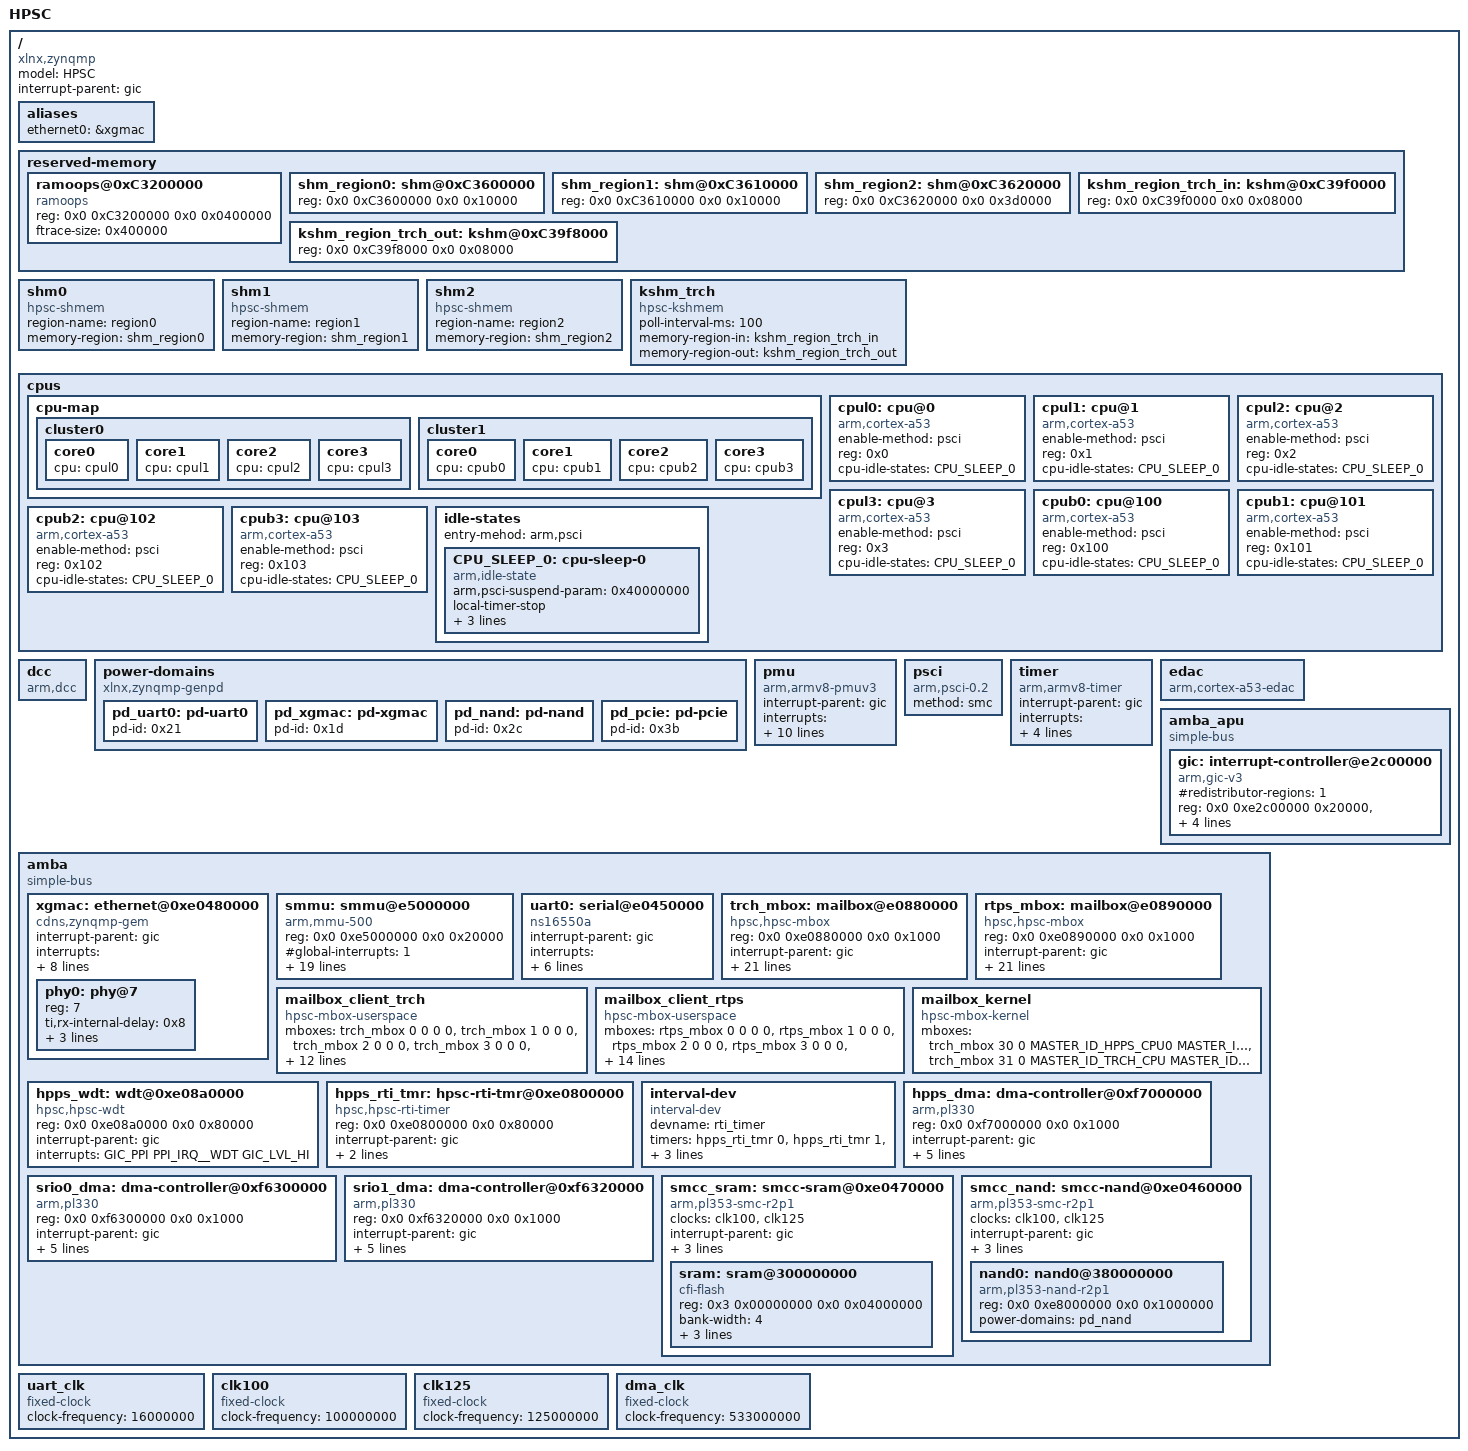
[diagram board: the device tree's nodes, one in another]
/dts-v1/;

#include <dt-bindings/phy/phy.h>

/* Copies from Qemu Device Tree repo */
#include "hpsc-irqs.dtsh"
#include "hpsc-busids.dtsh"

#include "mailbox-map.h" /* same file also present in other subsystems */

#define GIC_SPI 0
#define GIC_PPI 1
#define GIC_EDGE_RISE 1
#define GIC_EDGE_FALL 2
#define GIC_EDGE_BOTH 3
#define GIC_LVL_HI 4
#define GIC_LVL_LO 8

/ {
	model = "HPSC";
	compatible = "xlnx,zynqmp";
	#address-cells = <2>;
	#size-cells = <2>;

	interrupt-parent = <&gic>;
	aliases {
		ethernet0 = &xgmac;
	};

        /* NOTE: memory { } nodes appended by u-boot from its device tree */

	reserved-memory { /* TOOD: confirm that this is respected, also can/should this be in u-boot DT? */
		#address-cells = <2>;
		#size-cells = <2>;
		ranges;

		ramoops@0xC3200000 {
			compatible = "ramoops";
			reg = <0x0 0xC3200000 0x0 0x0400000>;
			ftrace-size = <0x400000>;
		};

		/* These shared memory regions cover the following range: */
		/* reg = <0x0 0xbf800000 0x0 0x400000>; */
		/* First part of the memory is for userspace */
		/* outbound to TRCH */
		shm_region0: shm@0xC3600000 {
			reg = <0x0 0xC3600000 0x0 0x10000>;
		};
		/* inbound from TRCH */
		shm_region1: shm@0xC3610000 {
			reg = <0x0 0xC3610000 0x0 0x10000>;
		};
		/* currently unused */
		shm_region2: shm@0xC3620000 {
			reg = <0x0 0xC3620000 0x0 0x3d0000>;
		};
		/* Remaining part of the memory is for the kernel */
		kshm_region_trch_in: kshm@0xC39f0000 {
			reg = <0x0 0xC39f0000 0x0 0x08000>;
		};
		kshm_region_trch_out: kshm@0xC39f8000 {
			reg = <0x0 0xC39f8000 0x0 0x08000>;
		};
	};

	shm0 {
		compatible = "hpsc-shmem";
		region-name = "region0";
		memory-region = <&shm_region0>;
	};
	shm1 {
		compatible = "hpsc-shmem";
		region-name = "region1";
		memory-region = <&shm_region1>;
	};
	shm2 {
		compatible = "hpsc-shmem";
		region-name = "region2";
		memory-region = <&shm_region2>;
	};
	kshm_trch {
		compatible = "hpsc-kshmem";
		poll-interval-ms = <100>;
		memory-region-in = <&kshm_region_trch_in>;
		memory-region-out = <&kshm_region_trch_out>;
	};

	cpus {
		#address-cells = <1>;
		#size-cells = <0>;

		cpu-map {
			cluster0 {
				core0 {
					cpu = <&cpul0>;
				};
				core1 {
					cpu = <&cpul1>;
				};
				core2 {
					cpu = <&cpul2>;
				};
				core3 {
					cpu = <&cpul3>;
				};
			};
			cluster1 {
				core0 {
					cpu = <&cpub0>;
				};
				core1 {
					cpu = <&cpub1>;
				};
				core2 {
					cpu = <&cpub2>;
				};
				core3 {
					cpu = <&cpub3>;
				};
			};

		};
         
		cpul0: cpu@0 {
			compatible = "arm,cortex-a53", "arm,armv8";
			device_type = "cpu";
			enable-method = "psci";
			reg = <0x0>;
			cpu-idle-states = <&CPU_SLEEP_0>;
		};

		cpul1: cpu@1 {
			compatible = "arm,cortex-a53", "arm,armv8";
			device_type = "cpu";
			enable-method = "psci";
			reg = <0x1>;
			cpu-idle-states = <&CPU_SLEEP_0>;
		};

		cpul2: cpu@2 {
			compatible = "arm,cortex-a53", "arm,armv8";
			device_type = "cpu";
			enable-method = "psci";
			reg = <0x2>;
			cpu-idle-states = <&CPU_SLEEP_0>;
		};

		cpul3: cpu@3 {
			compatible = "arm,cortex-a53", "arm,armv8";
			device_type = "cpu";
			enable-method = "psci";
			reg = <0x3>;
			cpu-idle-states = <&CPU_SLEEP_0>;
		};

		cpub0: cpu@100 {
			compatible = "arm,cortex-a53", "arm,armv8";
			device_type = "cpu";
			enable-method = "psci";
			reg = <0x100>;
			cpu-idle-states = <&CPU_SLEEP_0>;
		};

		cpub1: cpu@101 {
			compatible = "arm,cortex-a53", "arm,armv8";
			device_type = "cpu";
			enable-method = "psci";
			reg = <0x101>;
			cpu-idle-states = <&CPU_SLEEP_0>;
		};

		cpub2: cpu@102 {
			compatible = "arm,cortex-a53", "arm,armv8";
			device_type = "cpu";
			enable-method = "psci";
			reg = <0x102>;
			cpu-idle-states = <&CPU_SLEEP_0>;
		};

		cpub3: cpu@103 {
			compatible = "arm,cortex-a53", "arm,armv8";
			device_type = "cpu";
			enable-method = "psci";
			reg = <0x103>;
			cpu-idle-states = <&CPU_SLEEP_0>;
		};

		idle-states {
			entry-mehod = "arm,psci";

			CPU_SLEEP_0: cpu-sleep-0 {
				compatible = "arm,idle-state";
				arm,psci-suspend-param = <0x40000000>;
				local-timer-stop;
				entry-latency-us = <300>;
				exit-latency-us = <600>;
				min-residency-us = <800000>;
			};
		};
	};

	dcc: dcc {
		compatible = "arm,dcc";
		status = "okay";
	};

	power-domains {
		compatible = "xlnx,zynqmp-genpd";

		pd_uart0: pd-uart0 {
			#power-domain-cells = <0x0>;
			pd-id = <0x21>;
		};

		pd_xgmac: pd-xgmac {
			#power-domain-cells = <0x0>;
			pd-id = <0x1d>;
		};

		pd_nand: pd-nand {
			#power-domain-cells = <0x0>;
			pd-id = <0x2c>;
		};

		pd_pcie: pd-pcie {
			#power-domain-cells = <0x0>;
			pd-id = <0x3b>;
		};
	};

	pmu {
		compatible = "arm,armv8-pmuv3";
		interrupt-parent = <&gic>;
		interrupts = <GIC_SPI HPPS_IRQ__PMU_0 GIC_LVL_HI>,
			     <GIC_SPI HPPS_IRQ__PMU_1 GIC_LVL_HI>,
			     <GIC_SPI HPPS_IRQ__PMU_2 GIC_LVL_HI>,
			     <GIC_SPI HPPS_IRQ__PMU_3 GIC_LVL_HI>,
			     <GIC_SPI HPPS_IRQ__PMU_4 GIC_LVL_HI>,
			     <GIC_SPI HPPS_IRQ__PMU_5 GIC_LVL_HI>,
			     <GIC_SPI HPPS_IRQ__PMU_6 GIC_LVL_HI>,
			     <GIC_SPI HPPS_IRQ__PMU_7 GIC_LVL_HI>;
		interrupt-affinity = <&cpul0>, <&cpul1>, <&cpul2>, <&cpul3>,
                                     <&cpub0>, <&cpub1>, <&cpub2>, <&cpub3>;
	};

	psci {
		compatible = "arm,psci-0.2";
		method = "smc";
	};

	timer {
		compatible = "arm,armv8-timer";
		interrupt-parent = <&gic>;
		interrupts = <GIC_PPI PPI_IRQ__TIMER_SEC  GIC_LVL_LO>,
			     <GIC_PPI PPI_IRQ__TIMER_PHYS GIC_LVL_LO>,
			     <GIC_PPI PPI_IRQ__TIMER_VIRT GIC_LVL_LO>,
			     <GIC_PPI PPI_IRQ__TIMER_HYP  GIC_LVL_LO>;
	};

	edac {
		compatible = "arm,cortex-a53-edac";
	};

	amba_apu: amba_apu {
		compatible = "simple-bus";
		#address-cells = <2>;
		#size-cells = <1>;
		ranges = <0 0 0 0 0xffffffff>;

		gic: interrupt-controller@e2c00000{
			compatible = "arm,gic-v3"; 
			#interrupt-cells = <3>;
			#redistributor-regions = <1>;
			reg = <0x0 0xe2c00000 0x20000>,
			      <0x0 0xe2d00000 0x100000>;
			interrupt-controller;
			interrupts = <GIC_PPI PPI_IRQ__GIC_MAINT GIC_LVL_HI>;
		};
	};

	amba: amba {
		compatible = "simple-bus";
		#address-cells = <2>;
		#size-cells = <2>;
		ranges;

		xgmac: ethernet@0xe0480000{
			compatible = "cdns,zynqmp-gem";
			status = "okay";
			interrupt-parent = <&gic>;
			interrupts = <GIC_SPI HPPS_IRQ__XGMAC      GIC_LVL_HI>,
                                     <GIC_SPI HPPS_IRQ__XGMAC_WAKE GIC_LVL_HI>;
			reg = <0x0 0xe0480000 0x0 0x1000>;
			clocks = <&clk125>, <&clk125>, <&clk125>;
			clock-names = "pclk", "hclk", "tx_clk";
			#address-cells = <1>;
			#size-cells = <0>;
			iommus = <&smmu MASTER_ID_XGMAC>;
			power-domains = <&pd_xgmac>;
			phy-handle = <&phy0>;
			phy-mode = "rgmii-id";

			phy0: phy@7 {
				reg = <7>;
				ti,rx-internal-delay = <0x8>;
				ti,tx-internal-delay = <0xa>;
				ti,fifo-depth = <0x1>;
				ti,rxctrl-strap-worka;
			};
		};

#if 0 /* TODO */
		pcie: pcie@0xe5330000 {
			compatible = "xlnx,nwl-pcie-2.11";
			status = "okay";
			#address-cells = <3>;
			#size-cells = <2>;
			#interrupt-cells = <1>;
			msi-controller;
			device_type = "pci";
			interrupt-parent = <&gic>;
			interrupts = <GIC_SPI ? GIC_LVL_HI>,
				     <GIC_SPI ? GIC_LVL_HI>,
				     <GIC_SPI ? GIC_LVL_HI>,
				     <GIC_SPI ? GIC_LVL_HI>,	/* MSI_1 [63...32] */
				     <GIC_SPI ? GIC_LVL_HI>;	/* MSI_0 [31...0] */
			interrupt-names = "misc","dummy","intx", "msi1", "msi0";
			msi-parent = <&pcie>;
			reg = <0x0 0xe5330000 0x0 0x1000>,
			      <0x0 0xe53d0000 0x0 0x1000>,
			      <0x80 0x00000000 0x0 0x1000000>;
			reg-names = "breg", "pcireg", "cfg";
			ranges = <0x02000000 0x00000000 0xe0000000 0x00000000 0xe0000000 0x00000000 0x10000000	/* non-prefetchable memory */
				  0x43000000 0x00000006 0x00000000 0x00000006 0x00000000 0x00000002 0x00000000>;/* prefetchable memory */
			interrupt-map-mask = <0x0 0x0 0x0 0x7>;
			interrupt-map = <0x0 0x0 0x0 0x1 &pcie_intc 0x1>,
					<0x0 0x0 0x0 0x2 &pcie_intc 0x2>,
					<0x0 0x0 0x0 0x3 &pcie_intc 0x3>,
					<0x0 0x0 0x0 0x4 &pcie_intc 0x4>;
			power-domains = <&pd_pcie>;
			pcie_intc: legacy-interrupt-controller {
				interrupt-controller;
				#address-cells = <0>;
				#interrupt-cells = <1>;
			};
		};
#endif

		smmu: smmu@e5000000{
			compatible = "arm,mmu-500";
			reg = <0x0 0xe5000000 0x0 0x20000>;
			#iommu-cells = <1>;
			#global-interrupts = <1>;
			interrupt-parent = <&gic>;
			interrupts = <GIC_SPI HPPS_IRQ__HPPS_SMMU_GLOB GIC_LVL_HI>, /* global irq */
                                /* context IRQs */
                                <GIC_SPI HPPS_IRQ__HPPS_SMMU_CB_0 GIC_LVL_HI>,
                                <GIC_SPI HPPS_IRQ__HPPS_SMMU_CB_1 GIC_LVL_HI>,
                                <GIC_SPI HPPS_IRQ__HPPS_SMMU_CB_2 GIC_LVL_HI>,
                                <GIC_SPI HPPS_IRQ__HPPS_SMMU_CB_3 GIC_LVL_HI>,
                                <GIC_SPI HPPS_IRQ__HPPS_SMMU_CB_4 GIC_LVL_HI>,
                                <GIC_SPI HPPS_IRQ__HPPS_SMMU_CB_5 GIC_LVL_HI>,
                                <GIC_SPI HPPS_IRQ__HPPS_SMMU_CB_6 GIC_LVL_HI>,
                                <GIC_SPI HPPS_IRQ__HPPS_SMMU_CB_7 GIC_LVL_HI>,
                                <GIC_SPI HPPS_IRQ__HPPS_SMMU_CB_8 GIC_LVL_HI>,
                                <GIC_SPI HPPS_IRQ__HPPS_SMMU_CB_9 GIC_LVL_HI>,
                                <GIC_SPI HPPS_IRQ__HPPS_SMMU_CB_10 GIC_LVL_HI>,
                                <GIC_SPI HPPS_IRQ__HPPS_SMMU_CB_11 GIC_LVL_HI>,
                                <GIC_SPI HPPS_IRQ__HPPS_SMMU_CB_12 GIC_LVL_HI>,
                                <GIC_SPI HPPS_IRQ__HPPS_SMMU_CB_13 GIC_LVL_HI>,
                                <GIC_SPI HPPS_IRQ__HPPS_SMMU_CB_14 GIC_LVL_HI>,
                                <GIC_SPI HPPS_IRQ__HPPS_SMMU_CB_15 GIC_LVL_HI>;
		};

		uart0: serial@e0450000 {
			compatible = "ns16550a";
			/* compatible = "snps,dw-apb-uart"; */ /* TODO: fails with unassigned access */
			status = "okay";
			interrupt-parent = <&gic>;
			interrupts = <GIC_SPI HPPS_IRQ__HPPS_UART0_0 GIC_LVL_HI>;
			reg = <0x0 0xe0450000 0x0 0x1000>;
			current-speed = <125000>;
			reg-shift = <2>;
			clocks = <&uart_clk &uart_clk>;
			clock-names = "uart_clk", "pclk";
			power-domains = <&pd_uart0>;
		};

		trch_mbox: mailbox@e0880000{
			compatible = "hpsc,hpsc-mbox";
                        reg = <0x0 0xe0880000 0x0 0x1000>;
			interrupt-parent = <&gic>;

			/* Define all, but only two will be used, selected by
			 * interrupt-idx-{rcv,ack} props. We can't only list
			 * the two in this list, because the driver needs the
			 * actual within-ip-block index of the interrupt (and
			 * if we do, we'd still need an extra property to define
			 * the starting irq number, which is worse. */
			interrupts = <GIC_SPI HPPS_IRQ__HT_MBOX_0  GIC_LVL_HI>,
				     <GIC_SPI HPPS_IRQ__HT_MBOX_1  GIC_LVL_HI>,
				     <GIC_SPI HPPS_IRQ__HT_MBOX_2  GIC_LVL_HI>,
				     <GIC_SPI HPPS_IRQ__HT_MBOX_3  GIC_LVL_HI>,
				     <GIC_SPI HPPS_IRQ__HT_MBOX_4  GIC_LVL_HI>,
				     <GIC_SPI HPPS_IRQ__HT_MBOX_5  GIC_LVL_HI>,
				     <GIC_SPI HPPS_IRQ__HT_MBOX_6  GIC_LVL_HI>,
				     <GIC_SPI HPPS_IRQ__HT_MBOX_7  GIC_LVL_HI>,
				     <GIC_SPI HPPS_IRQ__HT_MBOX_8  GIC_LVL_HI>,
				     <GIC_SPI HPPS_IRQ__HT_MBOX_9  GIC_LVL_HI>,
				     <GIC_SPI HPPS_IRQ__HT_MBOX_10 GIC_LVL_HI>,
				     <GIC_SPI HPPS_IRQ__HT_MBOX_11 GIC_LVL_HI>,
				     <GIC_SPI HPPS_IRQ__HT_MBOX_12 GIC_LVL_HI>,
				     <GIC_SPI HPPS_IRQ__HT_MBOX_13 GIC_LVL_HI>,
				     <GIC_SPI HPPS_IRQ__HT_MBOX_14 GIC_LVL_HI>,
				     <GIC_SPI HPPS_IRQ__HT_MBOX_15 GIC_LVL_HI>;

			/* Map all instances onto one pair of IRQs,
			 * this pair must be not be used by other subsystems */
			interrupt-idx-rcv = <HPPS_MBOX0_INT_EVT0__HPPS_SMP_SSW>;
			interrupt-idx-ack = <HPPS_MBOX0_INT_EVT1__HPPS_SMP_SSW>;

			#mbox-cells = <4>;
                        /* instance index,
                           owner (0=do not claim, else set owner reg to this value),
                           source,
                           destination (if dest is not 0,
                                          if not owner, then dest reg checked against this value,
                                          if owner and, dest reg is set to this value) */
		};

		rtps_mbox: mailbox@e0890000 {
			compatible = "hpsc,hpsc-mbox";
                        reg = <0x0 0xe0890000 0x0 0x1000>;
			interrupt-parent = <&gic>;
			interrupts = <GIC_SPI HPPS_IRQ__HR_MBOX_0  GIC_LVL_HI>,
				     <GIC_SPI HPPS_IRQ__HR_MBOX_1  GIC_LVL_HI>,
				     <GIC_SPI HPPS_IRQ__HR_MBOX_2  GIC_LVL_HI>,
				     <GIC_SPI HPPS_IRQ__HR_MBOX_3  GIC_LVL_HI>,
				     <GIC_SPI HPPS_IRQ__HR_MBOX_4  GIC_LVL_HI>,
				     <GIC_SPI HPPS_IRQ__HR_MBOX_5  GIC_LVL_HI>,
				     <GIC_SPI HPPS_IRQ__HR_MBOX_6  GIC_LVL_HI>,
				     <GIC_SPI HPPS_IRQ__HR_MBOX_7  GIC_LVL_HI>,
				     <GIC_SPI HPPS_IRQ__HR_MBOX_8  GIC_LVL_HI>,
				     <GIC_SPI HPPS_IRQ__HR_MBOX_9  GIC_LVL_HI>,
				     <GIC_SPI HPPS_IRQ__HR_MBOX_10 GIC_LVL_HI>,
				     <GIC_SPI HPPS_IRQ__HR_MBOX_11 GIC_LVL_HI>,
				     <GIC_SPI HPPS_IRQ__HR_MBOX_12 GIC_LVL_HI>,
				     <GIC_SPI HPPS_IRQ__HR_MBOX_13 GIC_LVL_HI>,
				     <GIC_SPI HPPS_IRQ__HR_MBOX_14 GIC_LVL_HI>,
				     <GIC_SPI HPPS_IRQ__HR_MBOX_15 GIC_LVL_HI>;

			interrupt-idx-rcv = <HPPS_MBOX1_INT_EVT0__HPPS_SMP_SSW>;
			interrupt-idx-ack = <HPPS_MBOX1_INT_EVT1__HPPS_SMP_SSW>;

			#mbox-cells = <GIC_LVL_HI>;
		};

		mailbox_client_trch {
			compatible = "hpsc-mbox-userspace";
			mboxes =  /* ip block, instance index, owner, src, dest */
				    <&trch_mbox   0     0                    0 0>,
				    <&trch_mbox   1     0                    0 0>,
				    <&trch_mbox   2     0                    0 0>,
				    <&trch_mbox   3     0                    0 0>,
				    <&trch_mbox   4     0                    0 0>,
				    <&trch_mbox   5     0                    0 0>,
				    <&trch_mbox   6     0                    0 0>,
				    <&trch_mbox   7     0                    0 0>,
				    <&trch_mbox   8     0                    0 0>,
				    <&trch_mbox   9     0                    0 0>,
				    <&trch_mbox  10     0                    0 0>,
				    <&trch_mbox  11     0                    0 0>,
				    <&trch_mbox  12     0                    0 0>,
				    <&trch_mbox  13     0                    0 0>,
				    <&trch_mbox  14     0                    0 0>,
				    <&trch_mbox  15     0                    0 0>,
				    <&trch_mbox  16     0                    0 0>,
				    <&trch_mbox  17     0                    0 0>,
				    <&trch_mbox  18     0                    0 0>,
				    <&trch_mbox  19     0                    0 0>,
				    <&trch_mbox  20     0                    0 0>,
				    <&trch_mbox  21     0                    0 0>,
				    <&trch_mbox  22     0                    0 0>,
				    <&trch_mbox  23     0                    0 0>,
				    <&trch_mbox  24     0                    0 0>,
				    <&trch_mbox  25     0                    0 0>,
				    <&trch_mbox  26     0                    0 0>,
				    <&trch_mbox  27     0                    0 0>;
				    /* Reserved for ATF
				     * <&trch_mbox  28     0                    0 0>,
				     * <&trch_mbox  29     0                    0 0>;
				     */
				    /* Reserved for in-kernel SSW (see below)
				     * <&trch_mbox  30     0                    0 0>,
				     * <&trch_mbox  31     0                    0 0>;
				     */
			/* NOTE: destination is just an identifier, mboxes accessible from any core */
			/* names optional, if not given, dev files named 'mbox%u' by index */
			/*
			mbox-names = "mbox_trch_out",
				     "mbox_trch_in",
				     "mbox_rtps_out",
				     "mbox_rtps_in",
				     "mbox_own_trch_out",
				     "mbox_own_trch_in";
			*/
		};

		mailbox_client_rtps {
			compatible = "hpsc-mbox-userspace";
			mboxes =  /* ip block, instance index, owner, src, dest */
				    <&rtps_mbox   0     0                    0 0>,
				    <&rtps_mbox   1     0                    0 0>,
				    <&rtps_mbox   2     0                    0 0>,
				    <&rtps_mbox   3     0                    0 0>,
				    <&rtps_mbox   4     0                    0 0>,
				    <&rtps_mbox   5     0                    0 0>,
				    <&rtps_mbox   6     0                    0 0>,
				    <&rtps_mbox   7     0                    0 0>,
				    <&rtps_mbox   8     0                    0 0>,
				    <&rtps_mbox   9     0                    0 0>,
				    <&rtps_mbox  10     0                    0 0>,
				    <&rtps_mbox  11     0                    0 0>,
				    <&rtps_mbox  12     0                    0 0>,
				    <&rtps_mbox  13     0                    0 0>,
				    <&rtps_mbox  14     0                    0 0>,
				    <&rtps_mbox  15     0                    0 0>,
				    <&rtps_mbox  16     0                    0 0>,
				    <&rtps_mbox  17     0                    0 0>,
				    <&rtps_mbox  18     0                    0 0>,
				    <&rtps_mbox  19     0                    0 0>,
				    <&rtps_mbox  20     0                    0 0>,
				    <&rtps_mbox  21     0                    0 0>,
				    <&rtps_mbox  22     0                    0 0>,
				    <&rtps_mbox  23     0                    0 0>,
				    <&rtps_mbox  24     0                    0 0>,
				    <&rtps_mbox  25     0                    0 0>,
				    <&rtps_mbox  26     0                    0 0>,
				    <&rtps_mbox  27     0                    0 0>,
				    <&rtps_mbox  28     0                    0 0>,
				    <&rtps_mbox  29     0                    0 0>,
				    <&rtps_mbox  30     0                    0 0>,
				    <&rtps_mbox  31     0                    0 0>;
		};

		mailbox_kernel {
			compatible = "hpsc-mbox-kernel";
			mboxes =  /* ip block, instance index, owner, src, dest */
				    <&trch_mbox  30     0  MASTER_ID_HPPS_CPU0 MASTER_ID_TRCH_CPU>,
				    <&trch_mbox  31     0  MASTER_ID_TRCH_CPU  MASTER_ID_HPPS_CPU0>;
		};

		hpps_wdt: wdt@0xe08a0000{
			compatible = "hpsc,hpsc-wdt";
			reg = <0x0 0xe08a0000 0x0 0x80000>;
			interrupt-parent = <&gic>;
			interrupts = <GIC_PPI PPI_IRQ__WDT GIC_LVL_HI>;
		};

		hpps_rti_tmr: hpsc-rti-tmr@0xe0800000{
			compatible = "hpsc,hpsc-rti-timer";
			reg = <0x0 0xe0800000 0x0 0x80000>;
			interrupt-parent = <&gic>;
			interrupts = <GIC_PPI PPI_IRQ__RTI_TIMER GIC_EDGE_RISE>;
			#timer-cells = <1>; /* cpu index */
		};

		interval-dev {
			compatible = "interval-dev";
			devname = "rti_timer";
			timers = <&hpps_rti_tmr 0>,
				 <&hpps_rti_tmr 1>,
				 <&hpps_rti_tmr 2>,
				 <&hpps_rti_tmr 3>,
				 <&hpps_rti_tmr 4>,
				 <&hpps_rti_tmr 5>,
				 <&hpps_rti_tmr 6>,
				 <&hpps_rti_tmr 7>;
		};

		hpps_dma: dma-controller@0xf7000000 {
			#dma-cells = <1>;
			compatible = "arm,pl330", "arm,primecell"; /* primecell spec required */
			reg = <0x0 0xf7000000 0x0 0x1000>;
			interrupt-parent = <&gic>;
			interrupts = <GIC_SPI HPPS_IRQ__HPPS_DMA_ABORT GIC_LVL_HI>,
				     <GIC_SPI HPPS_IRQ__HPPS_DMA_EV0   GIC_LVL_HI>;
			iommus = <&smmu MASTER_ID_HPPS_DMA>;
			clocks = <&dma_clk>;
			clock-names = "apb_pclk"; /* required, because amba code looks for it by name */
		};

		srio0_dma: dma-controller@0xf6300000{
			#dma-cells = <1>;
			compatible = "arm,pl330", "arm,primecell"; /* primecell spec required */
			reg = <0x0 0xf6300000 0x0 0x1000>;
			interrupt-parent = <&gic>;
			interrupts = <GIC_SPI HPPS_IRQ__SRIO0_DMA_ABORT GIC_LVL_HI>,
				     <GIC_SPI HPPS_IRQ__SRIO0_DMA_EV0   GIC_LVL_HI>;
			iommus = <&smmu MASTER_ID_SRIO0_DMA>;
			clocks = <&dma_clk>;
			clock-names = "apb_pclk"; /* required, because amba code looks for it by name */
		};

		srio1_dma: dma-controller@0xf6320000{
			#dma-cells = <1>;
			compatible = "arm,pl330", "arm,primecell"; /* primecell spec required */
			reg = <0x0 0xf6320000 0x0 0x1000>;
			interrupt-parent = <&gic>;
			interrupts = <GIC_SPI HPPS_IRQ__SRIO1_DMA_ABORT GIC_LVL_HI>,
				     <GIC_SPI HPPS_IRQ__SRIO1_DMA_EV0 GIC_LVL_HI>;
			iommus = <&smmu MASTER_ID_SRIO1_DMA>;
			clocks = <&dma_clk>;
			clock-names = "apb_pclk"; /* required, because amba code looks for it by name */
		};
		smcc_sram: smcc-sram@0xe0470000{
			#address-cells = <2>;
			#size-cells = <2>; 
			status = "okay";
			clocks = <&clk100>, <&clk125>;
			clock-names = "aclk", "memclk";
			/* iommus = <&smmu MASTER_ID_SMC>; */ /* not connected to an MMU TBU */
			compatible = "arm,pl353-smc-r2p1";
			interrupt-parent = <&gic>;
			interrupts = <GIC_SPI HPPS_IRQ__HPPS_SMC_SRAM GIC_LVL_HI>;
			ranges ;
			reg = <0x0 0xe0470000 0x0 0x1000>;
			sram: sram@300000000 {
				status = "okay";
				compatible = "cfi-flash";
				reg = <0x3 0x00000000 0x0 0x04000000>;
				#address-cells = <0x2>; 
				#size-cells = <0x1>; 
				bank-width = <4>;
				power-domains = <&pd_nand>;
				arm,sram-cycle-t0 = <1>;
				arm,sram-cycle-t1 = <1>;
			};
		};
		smcc_nand: smcc-nand@0xe0460000{
			#address-cells = <2>;
			#size-cells = <2>; 
			status = "okay";
			clocks = <&clk100>, <&clk125>;
			clock-names = "aclk", "memclk";
			/* iommus = <&smmu MASTER_ID_SMC>; */ /* not connected to an MMU TBU */
			compatible = "arm,pl353-smc-r2p1";
			interrupt-parent = <&gic>;
			interrupts = <GIC_SPI HPPS_IRQ__HPPS_SMC_NAND GIC_LVL_HI>;
			ranges ;
			reg = <0x0 0xe0460000 0x0 0x1000>;
			nand0: nand0@380000000 {
				status = "okay";
				compatible = "arm,pl353-nand-r2p1";
				reg = <0x0 0xe8000000 0x0 0x1000000>;
				#address-cells = <0x2>; 
				#size-cells = <0x1>; 
				power-domains = <&pd_nand>;
			};
		};
	};

	uart_clk: uart_clk {
		compatible = "fixed-clock";
		#clock-cells = <0>;
		clock-frequency = <16000000>;
	};
	clk100: clk100 {
		compatible = "fixed-clock";
		#clock-cells = <0>;
		clock-frequency = <100000000>;
	};
	clk125: clk125 {
		compatible = "fixed-clock";
		#clock-cells = <0>;
		clock-frequency = <125000000>;
	};

	dma_clk: dma_clk {
		compatible = "fixed-clock";
		#clock-cells = <0x0>;
		clock-frequency = <533000000>;
	};
};
